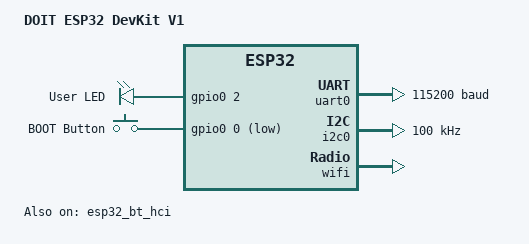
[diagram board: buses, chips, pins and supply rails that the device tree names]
/*
 * SPDX-License-Identifier: Apache-2.0
 */

/dts-v1/;

#include <espressif/esp32/esp32_wrover_e_n4r8.dtsi>
#include <espressif/partitions_0x1000_amp.dtsi>
#include <zephyr/dt-bindings/input/input-event-codes.h>
#include "my_board-pinctrl.dtsi"
/ {
        model = "DOIT ESP32 DevKit V1";
        compatible = "doit,esp32-devkit-v1";

        aliases {
                uart-0 = &uart0;
                i2c-0 = &i2c0;
                sw0 = &button0;
                led0 = &blue_led;
                watchdog0 = &wdt0;
        };

        leds {
                compatible = "gpio-leds";

                blue_led: blue_led {
                        gpios = <&gpio0 2 GPIO_ACTIVE_HIGH>;
                        label = "User LED";
                };
        };

        buttons {
                compatible = "gpio-keys";

                button0: button_0 {
                        gpios = <&gpio0 0 (GPIO_PULL_UP | GPIO_ACTIVE_LOW)>;
                        label = "BOOT Button";
                        zephyr,code = <INPUT_KEY_0>;
                };
        };

        chosen {
                zephyr,sram = &sram1;
                zephyr,console = &uart0;
                zephyr,shell-uart = &uart0;
                zephyr,flash = &flash0;
                zephyr,code-partition = &slot0_partition;
                zephyr,bt-hci = &esp32_bt_hci;
        };
};

&uart0 {
    status = "okay";
    current-speed = <115200>;
    pinctrl-0 = <&uart0_default>;
    pinctrl-names = "default";
};

&gpio0 {
        status = "okay";
};

&gpio1 {
        status = "okay";
};

&i2c0 {
    status = "okay";
    clock-frequency = <I2C_BITRATE_STANDARD>;
    pinctrl-0 = <&i2c0_default>;
    pinctrl-names = "default";
};

&esp32_bt_hci {
        status = "okay";
};

&wifi {
        status = "okay";
};
